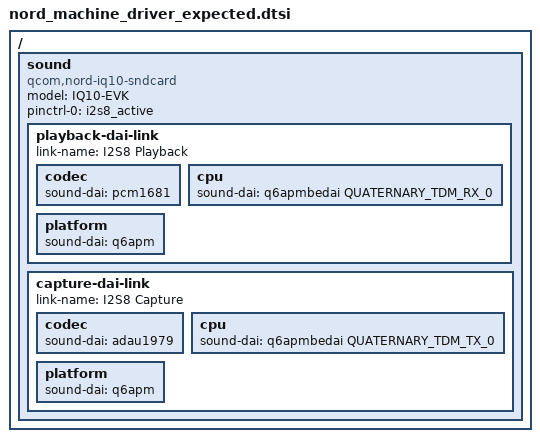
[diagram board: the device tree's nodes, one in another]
/*
 * Generated by Phase-2B WP5 machine_driver.
 * Deterministic. No timestamps.
 *
 * Nord IQ-10 AudioReach sound card. Wires LPASS I2S8 (pinctrl
 * <&i2s8_active>, WP3) to the two board codecs (&pcm1681
 * playback, &adau1979 capture, WP4) through the SoC-side
 * q6apmbedai / q6apm DAIs.
 */

/ {
	sound {
		compatible = "qcom,nord-iq10-sndcard";
		model = "IQ10-EVK";

		pinctrl-0 = <&i2s8_active>;
		pinctrl-names = "default";

		/* FIXME(i2s8_port_id): OCTONARY_TDM_RX_0 macro not in
		 * include/dt-bindings/sound/qcom,q6dsp-lpass-ports.h yet.
		 * Using QUATERNARY_TDM_RX_0 (72) as placeholder to match
		 * linux-nord/0004-*.patch:77. Correct binding requires an
		 * upstream q6dsp-lpass-ports.h extension for I2S8.
		 */
		playback-dai-link {
			link-name = "I2S8 Playback";

			codec {
				sound-dai = <&pcm1681>;
			};

			cpu {
				sound-dai = <&q6apmbedai QUATERNARY_TDM_RX_0>;
			};

			platform {
				sound-dai = <&q6apm>;
			};
		};

		/* FIXME(i2s8_port_id): OCTONARY_TDM_TX_0 macro not in
		 * include/dt-bindings/sound/qcom,q6dsp-lpass-ports.h yet.
		 * Using QUATERNARY_TDM_TX_0 (73) as placeholder to match
		 * linux-nord/0004-*.patch:93. Correct binding requires an
		 * upstream q6dsp-lpass-ports.h extension for I2S8.
		 */
		capture-dai-link {
			link-name = "I2S8 Capture";

			codec {
				sound-dai = <&adau1979>;
			};

			cpu {
				sound-dai = <&q6apmbedai QUATERNARY_TDM_TX_0>;
			};

			platform {
				sound-dai = <&q6apm>;
			};
		};
	};
};
